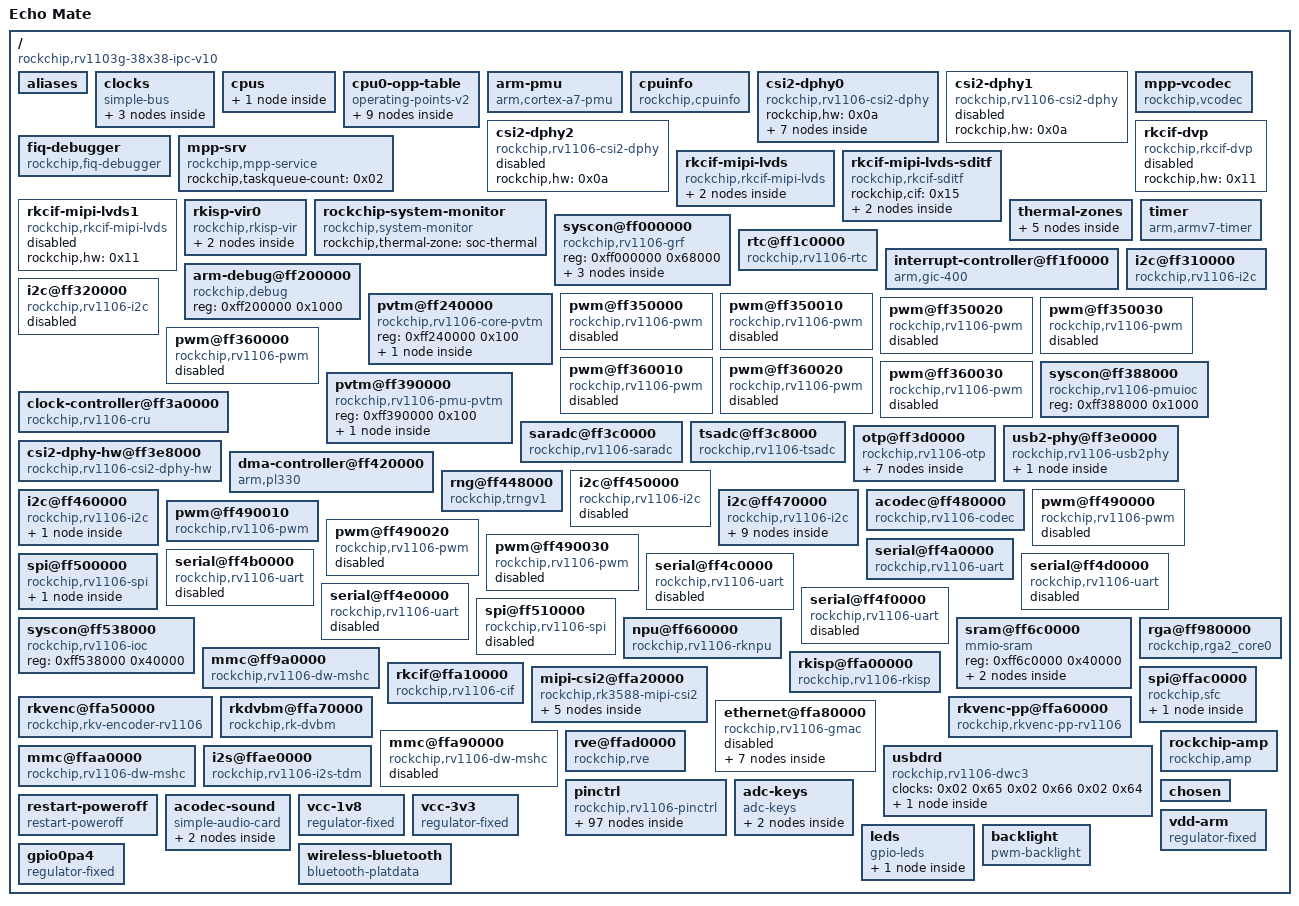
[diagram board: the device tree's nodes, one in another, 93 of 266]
/dts-v1/;

/ {
	#address-cells = <0x01>;
	#size-cells = <0x01>;
	compatible = "rockchip,rv1103g-38x38-ipc-v10\0rockchip,rv1106";
	interrupt-parent = <0x01>;
	model = "Echo Mate";

	aliases {
		csi2dphy0 = "/csi2-dphy0";
		csi2dphy1 = "/csi2-dphy1";
		csi2dphy2 = "/csi2-dphy2";
		ethernet0 = "/ethernet@ffa80000";
		gpio0 = "/pinctrl/gpio@ff380000";
		gpio1 = "/pinctrl/gpio@ff530000";
		gpio2 = "/pinctrl/gpio@ff540000";
		gpio3 = "/pinctrl/gpio@ff550000";
		gpio4 = "/pinctrl/gpio@ff560000";
		i2c0 = "/i2c@ff310000";
		i2c1 = "/i2c@ff320000";
		i2c2 = "/i2c@ff450000";
		i2c3 = "/i2c@ff460000";
		i2c4 = "/i2c@ff470000";
		mmc0 = "/mmc@ffa90000";
		mmc1 = "/mmc@ffaa0000";
		mmc2 = "/mmc@ff9a0000";
		pwm0 = "/pwm@ff350000";
		pwm1 = "/pwm@ff350010";
		pwm2 = "/pwm@ff350020";
		pwm3 = "/pwm@ff350030";
		pwm4 = "/pwm@ff360000";
		pwm5 = "/pwm@ff360010";
		pwm6 = "/pwm@ff360020";
		pwm7 = "/pwm@ff360030";
		pwm8 = "/pwm@ff490000";
		pwm9 = "/pwm@ff490010";
		pwm10 = "/pwm@ff490020";
		pwm11 = "/pwm@ff490030";
		rkcif_mipi_lvds0 = "/rkcif-mipi-lvds";
		rkcif_mipi_lvds1 = "/rkcif-mipi-lvds1";
		serial0 = "/serial@ff4a0000";
		serial1 = "/serial@ff4b0000";
		serial2 = "/serial@ff4c0000";
		serial3 = "/serial@ff4d0000";
		serial4 = "/serial@ff4e0000";
		serial5 = "/serial@ff4f0000";
		spi0 = "/spi@ff500000";
		spi1 = "/spi@ff510000";
		spi2 = "/spi@ffac0000";
	};

	clocks {
		compatible = "simple-bus";

		pvtpll-0 {
			compatible = "fixed-clock";
			clock-frequency = <0x18701a80>;
			clock-output-names = "clk_pvtpll_0";
			#clock-cells = <0x00>;
		};

		pvtpll-1 {
			compatible = "fixed-clock";
			clock-frequency = <0x1908b100>;
			clock-output-names = "clk_pvtpll_1";
			#clock-cells = <0x00>;
		};

		oscillator {
			compatible = "fixed-clock";
			clock-frequency = <0x16e3600>;
			clock-output-names = "xin24m";
			#clock-cells = <0x00>;
		};
	};

	cpus {
		#address-cells = <0x01>;
		#size-cells = <0x00>;

		cpu@0 {
			device_type = "cpu";
			compatible = "arm,cortex-a7";
			reg = <0x00>;
			clocks = <0x02 0x05>;
			operating-points-v2 = <0x03>;
			cpu-supply = <0x04>;
			phandle = <0x06>;
		};
	};

	cpu0-opp-table {
		compatible = "operating-points-v2";
		opp-shared;
		rockchip,pvtpll-avg-offset = <0x4001c>;
		rockchip,pvtpll-min-rate = <0x10d880>;
		rockchip,pvtpll-volt-step = <0x30d4>;
		rockchip,grf = <0x05>;
		phandle = <0x03>;

		opp-408000000 {
			opp-hz = <0x00 0x18519600>;
			opp-microvolt = <0xcf850 0xcf850 0x100590>;
			clock-latency-ns = <0x9c40>;
		};

		opp-600000000 {
			opp-hz = <0x00 0x23c34600>;
			opp-microvolt = <0xcf850 0xcf850 0x100590>;
			clock-latency-ns = <0x9c40>;
		};

		opp-816000000 {
			opp-hz = <0x00 0x30a32c00>;
			opp-microvolt = <0xcf850 0xcf850 0x100590>;
			clock-latency-ns = <0x9c40>;
			opp-suspend;
		};

		opp-1104000000 {
			opp-hz = <0x00 0x41cdb400>;
			opp-microvolt = <0xcf850 0xcf850 0x100590>;
			clock-latency-ns = <0x9c40>;
		};

		opp-1200000000 {
			opp-hz = <0x00 0x47868c00>;
			opp-microvolt = <0xcf850 0xcf850 0x100590>;
			clock-latency-ns = <0x9c40>;
		};

		opp-1296000000 {
			opp-hz = <0x00 0x4d3f6400>;
			opp-microvolt = <0xd59f8 0xcf850 0x100590>;
			clock-latency-ns = <0x9c40>;
		};

		opp-1416000000 {
			opp-hz = <0x00 0x54667200>;
			opp-microvolt = <0xe1d48 0xcf850 0x100590>;
			clock-latency-ns = <0x9c40>;
		};

		opp-1512000000 {
			opp-hz = <0x00 0x5a1f4a00>;
			opp-microvolt = <0xee098 0xcf850 0x100590>;
			clock-latency-ns = <0x9c40>;
		};

		opp-1608000000 {
			opp-hz = <0x00 0x5fd82200>;
			opp-microvolt = <0xf7314 0xcf850 0x100590>;
			clock-latency-ns = <0x9c40>;
		};
	};

	arm-pmu {
		compatible = "arm,cortex-a7-pmu";
		interrupts = <0x00 0x7e 0x04>;
		interrupt-affinity = <0x06>;
	};

	cpuinfo {
		compatible = "rockchip,cpuinfo";
		nvmem-cells = <0x07 0x08 0x09>;
		nvmem-cell-names = "id\0cpu-version\0cpu-code";
	};

	csi2-dphy0 {
		compatible = "rockchip,rv1106-csi2-dphy";
		rockchip,hw = <0x0a>;
		status = "okay";

		ports {
			#address-cells = <0x01>;
			#size-cells = <0x00>;

			port@0 {
				reg = <0x00>;
				#address-cells = <0x01>;
				#size-cells = <0x00>;

				endpoint@0 {
					reg = <0x00>;
					remote-endpoint = <0x0b>;
					data-lanes = <0x01 0x02>;
					phandle = <0x2f>;
				};

				endpoint@1 {
					reg = <0x01>;
					remote-endpoint = <0x0c>;
					data-lanes = <0x01 0x02>;
					phandle = <0x30>;
				};

				endpoint@2 {
					reg = <0x02>;
					remote-endpoint = <0x0d>;
					data-lanes = <0x01 0x02>;
					phandle = <0x31>;
				};
			};

			port@1 {
				reg = <0x01>;
				#address-cells = <0x01>;
				#size-cells = <0x00>;

				endpoint@0 {
					reg = <0x00>;
					remote-endpoint = <0x0e>;
					phandle = <0x4d>;
				};
			};
		};
	};

	csi2-dphy1 {
		compatible = "rockchip,rv1106-csi2-dphy";
		rockchip,hw = <0x0a>;
		status = "disabled";
	};

	csi2-dphy2 {
		compatible = "rockchip,rv1106-csi2-dphy";
		rockchip,hw = <0x0a>;
		status = "disabled";
	};

	fiq-debugger {
		compatible = "rockchip,fiq-debugger";
		rockchip,serial-id = <0x02>;
		rockchip,wake-irq = <0x00>;
		rockchip,irq-mode-enable = <0x01>;
		rockchip,baudrate = <0x1c200>;
		interrupts = <0x00 0x7d 0x04>;
		status = "okay";
	};

	mpp-srv {
		compatible = "rockchip,mpp-service";
		rockchip,taskqueue-count = <0x02>;
		status = "okay";
		phandle = <0x4f>;
	};

	mpp-vcodec {
		compatible = "rockchip,vcodec";
		status = "okay";
	};

	rkcif-dvp {
		compatible = "rockchip,rkcif-dvp";
		rockchip,hw = <0x11>;
		status = "disabled";
		phandle = <0x12>;
	};

	rkcif-mipi-lvds {
		compatible = "rockchip,rkcif-mipi-lvds";
		rockchip,hw = <0x11>;
		status = "okay";
		pinctrl-names = "default";
		pinctrl-0 = <0x13>;
		phandle = <0x15>;

		port {

			endpoint {
				remote-endpoint = <0x14>;
				phandle = <0x4e>;
			};
		};
	};

	rkcif-mipi-lvds-sditf {
		compatible = "rockchip,rkcif-sditf";
		rockchip,cif = <0x15>;
		status = "okay";

		port {

			endpoint {
				remote-endpoint = <0x16>;
				phandle = <0x1a>;
			};
		};
	};

	rkcif-mipi-lvds1 {
		compatible = "rockchip,rkcif-mipi-lvds";
		rockchip,hw = <0x11>;
		status = "disabled";
		phandle = <0x17>;
	};

	rkisp-vir0 {
		compatible = "rockchip,rkisp-vir";
		rockchip,hw = <0x18>;
		dvbm = <0x19>;
		status = "okay";

		port@0 {

			endpoint {
				remote-endpoint = <0x1a>;
				phandle = <0x16>;
			};
		};
	};

	rockchip-system-monitor {
		compatible = "rockchip,system-monitor";
		rockchip,thermal-zone = "soc-thermal";
	};

	thermal-zones {

		soc-thermal {
			polling-delay-passive = <0x14>;
			polling-delay = <0x3e8>;
			sustainable-power = <0x834>;
			thermal-sensors = <0x1b 0x00>;

			trips {

				trip-point-0 {
					temperature = <0x124f8>;
					hysteresis = <0x7d0>;
					type = "passive";
				};

				trip-point-1 {
					temperature = <0x14c08>;
					hysteresis = <0x7d0>;
					type = "passive";
				};

				soc-crit {
					temperature = <0x1c138>;
					hysteresis = <0x7d0>;
					type = "critical";
				};
			};
		};
	};

	timer {
		compatible = "arm,armv7-timer";
		interrupts = <0x01 0x0d 0x104>;
		clock-frequency = <0x16e3600>;
	};

	syscon@ff000000 {
		compatible = "rockchip,rv1106-grf\0syscon\0simple-mfd";
		reg = <0xff000000 0x68000>;
		phandle = <0x05>;

		grf-clock-controller {
			compatible = "rockchip,rv1106-grf-cru";
			#clock-cells = <0x01>;
			phandle = <0x48>;
		};

		reboot-mode {
			compatible = "syscon-reboot-mode";
			offset = <0x20200>;
			mode-bootloader = <0x5242c301>;
			mode-charge = <0x5242c30b>;
			mode-fastboot = <0x5242c309>;
			mode-loader = <0x5242c301>;
			mode-normal = <0x5242c300>;
			mode-recovery = <0x5242c303>;
			mode-ums = <0x5242c30c>;
			mode-panic = <0x5242c307>;
			mode-watchdog = <0x5242c308>;
			mode-uboot = <0x5242c30e>;
		};

		rknpor-powergood {
			compatible = "rockchip,rv1106-npor-powergood";
			interrupts = <0x00 0x56 0x04>;
			status = "okay";
		};
	};

	rtc@ff1c0000 {
		compatible = "rockchip,rv1106-rtc";
		reg = <0xff1c0000 0x1000>;
		rockchip,grf = <0x05>;
		interrupts = <0x00 0x62 0x04>;
		clocks = <0x02 0xef 0x02 0xee>;
		clock-names = "pclk_phy\0pclk_test";
		assigned-clocks = <0x02 0xef>;
		assigned-clock-rates = <0x16e3600>;
		status = "okay";
	};

	interrupt-controller@ff1f0000 {
		compatible = "arm,gic-400";
		interrupt-controller;
		#interrupt-cells = <0x03>;
		#address-cells = <0x00>;
		reg = <0xff1f1000 0x1000 0xff1f2000 0x2000 0xff1f4000 0x2000 0xff1f6000 0x2000>;
		interrupts = <0x01 0x09 0x104>;
		phandle = <0x01>;
	};

	arm-debug@ff200000 {
		compatible = "rockchip,debug";
		reg = <0xff200000 0x1000>;
	};

	pvtm@ff240000 {
		compatible = "rockchip,rv1106-core-pvtm";
		reg = <0xff240000 0x100>;
		#address-cells = <0x01>;
		#size-cells = <0x00>;

		pvtm@0 {
			reg = <0x00>;
			clocks = <0x02 0x40>;
			clock-names = "clk";
			resets = <0x02 0x6000e 0x02 0x6000f>;
			reset-names = "rst\0rst-p";
		};
	};

	i2c@ff310000 {
		compatible = "rockchip,rv1106-i2c\0rockchip,rk3399-i2c";
		reg = <0xff310000 0x1000>;
		interrupts = <0x00 0x12 0x04>;
		#address-cells = <0x01>;
		#size-cells = <0x00>;
		clocks = <0x02 0x2a 0x02 0x29>;
		clock-names = "i2c\0pclk";
		pinctrl-names = "default";
		pinctrl-0 = <0x1c>;
		status = "okay";
		clock-frequency = <0x186a0>;
	};

	i2c@ff320000 {
		compatible = "rockchip,rv1106-i2c\0rockchip,rk3399-i2c";
		reg = <0xff320000 0x1000>;
		interrupts = <0x00 0x13 0x04>;
		#address-cells = <0x01>;
		#size-cells = <0x00>;
		clocks = <0x02 0x78 0x02 0x77>;
		clock-names = "i2c\0pclk";
		pinctrl-names = "default";
		pinctrl-0 = <0x1d>;
		status = "disabled";
		clock-frequency = <0x186a0>;
	};

	pwm@ff350000 {
		compatible = "rockchip,rv1106-pwm\0rockchip,rk3328-pwm";
		reg = <0xff350000 0x10>;
		#pwm-cells = <0x03>;
		pinctrl-names = "active";
		pinctrl-0 = <0x1f>;
		clocks = <0x02 0x36 0x02 0x35>;
		clock-names = "pwm\0pclk";
		status = "disabled";
	};

	pwm@ff350010 {
		compatible = "rockchip,rv1106-pwm\0rockchip,rk3328-pwm";
		reg = <0xff350010 0x10>;
		#pwm-cells = <0x03>;
		pinctrl-names = "active";
		pinctrl-0 = <0x20>;
		clocks = <0x02 0x36 0x02 0x35>;
		clock-names = "pwm\0pclk";
		status = "disabled";
	};

	pwm@ff350020 {
		compatible = "rockchip,rv1106-pwm\0rockchip,rk3328-pwm";
		reg = <0xff350020 0x10>;
		#pwm-cells = <0x03>;
		pinctrl-names = "active";
		pinctrl-0 = <0x21>;
		clocks = <0x02 0x36 0x02 0x35>;
		clock-names = "pwm\0pclk";
		status = "disabled";
	};

	pwm@ff350030 {
		compatible = "rockchip,rv1106-pwm\0rockchip,rk3328-pwm";
		reg = <0xff350030 0x10>;
		interrupts = <0x00 0x1f 0x04 0x00 0x20 0x04>;
		#pwm-cells = <0x03>;
		pinctrl-names = "active";
		pinctrl-0 = <0x22>;
		clocks = <0x02 0x36 0x02 0x35>;
		clock-names = "pwm\0pclk";
		status = "disabled";
	};

	pwm@ff360000 {
		compatible = "rockchip,rv1106-pwm\0rockchip,rk3328-pwm";
		reg = <0xff360000 0x10>;
		#pwm-cells = <0x03>;
		pinctrl-names = "active";
		pinctrl-0 = <0x23>;
		clocks = <0x02 0x44 0x02 0x43>;
		clock-names = "pwm\0pclk";
		status = "disabled";
	};

	pwm@ff360010 {
		compatible = "rockchip,rv1106-pwm\0rockchip,rk3328-pwm";
		reg = <0xff360010 0x10>;
		#pwm-cells = <0x03>;
		pinctrl-names = "active";
		pinctrl-0 = <0x24>;
		clocks = <0x02 0x44 0x02 0x43>;
		clock-names = "pwm\0pclk";
		status = "disabled";
	};

	pwm@ff360020 {
		compatible = "rockchip,rv1106-pwm\0rockchip,rk3328-pwm";
		reg = <0xff360020 0x10>;
		#pwm-cells = <0x03>;
		pinctrl-names = "active";
		pinctrl-0 = <0x25 0x26>;
		clocks = <0x02 0x44 0x02 0x43>;
		clock-names = "pwm\0pclk";
		status = "disabled";
	};

	pwm@ff360030 {
		compatible = "rockchip,rv1106-pwm\0rockchip,rk3328-pwm";
		reg = <0xff360030 0x10>;
		interrupts = <0x00 0x21 0x04 0x00 0x22 0x04>;
		#pwm-cells = <0x03>;
		pinctrl-names = "active";
		pinctrl-0 = <0x27>;
		clocks = <0x02 0x44 0x02 0x43>;
		clock-names = "pwm\0pclk";
		status = "disabled";
	};

	syscon@ff388000 {
		compatible = "rockchip,rv1106-pmuioc\0syscon";
		reg = <0xff388000 0x1000>;
		phandle = <0x5d>;
	};

	pvtm@ff390000 {
		compatible = "rockchip,rv1106-pmu-pvtm";
		reg = <0xff390000 0x100>;
		#address-cells = <0x01>;
		#size-cells = <0x00>;

		pvtm@0 {
			reg = <0x01>;
			clocks = <0x02 0x7e 0x02 0x7f>;
			clock-names = "clk\0pclk";
			resets = <0x02 0x14 0x02 0x15>;
			reset-names = "rst\0rst-p";
		};
	};

	clock-controller@ff3a0000 {
		compatible = "rockchip,rv1106-cru";
		reg = <0xff3a0000 0x20000>;
		rockchip,grf = <0x05>;
		#clock-cells = <0x01>;
		#reset-cells = <0x01>;
		assigned-clocks = <0x02 0x04 0x02 0x03 0x02 0x05 0x02 0x39 0x02 0x3a 0x02 0x38 0x02 0x3c 0x02 0xcb 0x02 0x82 0x02 0x83>;
		assigned-clock-rates = <0x46cf7100 0x3b9aca00 0x41cdb400 0x17d78400 0xbebc200 0x5f5e100 0x11e1a300 0x5f5e100 0x5f5e100 0xbebc200>;
		phandle = <0x02>;
	};

	saradc@ff3c0000 {
		compatible = "rockchip,rv1106-saradc";
		reg = <0xff3c0000 0x200>;
		interrupts = <0x00 0x3e 0x04>;
		#io-channel-cells = <0x01>;
		clocks = <0x02 0x4d 0x02 0x4c>;
		clock-names = "saradc\0apb_pclk";
		resets = <0x02 0x48033>;
		reset-names = "saradc-apb";
		status = "okay";
		vref-supply = <0x28>;
		phandle = <0x68>;
	};

	tsadc@ff3c8000 {
		compatible = "rockchip,rv1106-tsadc";
		reg = <0xff3c8000 0x1000>;
		rockchip,grf = <0x05>;
		interrupts = <0x00 0x61 0x04>;
		clocks = <0x02 0x113 0x02 0x112 0x02 0x114>;
		clock-names = "tsadc\0apb_pclk\0tsen";
		assigned-clocks = <0x02 0x113 0x02 0x114>;
		assigned-clock-rates = <0xf4240 0xb71b00>;
		resets = <0x02 0x70021 0x02 0x70020>;
		reset-names = "tsadc\0tsadc-apb";
		#thermal-sensor-cells = <0x01>;
		rockchip,hw-tshut-temp = <0x1d4c0>;
		rockchip,hw-tshut-mode = <0x00>;
		rockchip,hw-tshut-polarity = <0x00>;
		status = "okay";
		phandle = <0x1b>;
	};

	otp@ff3d0000 {
		compatible = "rockchip,rv1106-otp";
		reg = <0xff3d0000 0x4000>;
		#address-cells = <0x01>;
		#size-cells = <0x01>;
		clocks = <0x02 0x107 0x02 0x106 0x02 0x105 0x02 0x10b 0x02 0x104 0x02 0x10c>;
		clock-names = "usr\0sbpi\0apb\0phy\0arb\0pmc";
		resets = <0x02 0x70026 0x02 0x70025 0x02 0x70023 0x02 0x7002e 0x02 0x7002b 0x02 0x7002f>;
		reset-names = "usr\0sbpi\0apb\0phy\0arb\0pmc";

		cpu-code@2 {
			reg = <0x02 0x02>;
			phandle = <0x09>;
		};

		cpu-version@8 {
			reg = <0x08 0x01>;
			bits = <0x03 0x03>;
			phandle = <0x08>;
		};

		id@a {
			reg = <0x0a 0x10>;
			phandle = <0x07>;
		};

		cpu-leakage@1a {
			reg = <0x1a 0x01>;
		};

		log-leakage@1b {
			reg = <0x1b 0x01>;
		};

		macphy-bgs@2d {
			reg = <0x2d 0x01>;
			phandle = <0x54>;
		};

		macphy-txlevel@2e {
			reg = <0x2e 0x02>;
			phandle = <0x55>;
		};
	};

	usb2-phy@ff3e0000 {
		compatible = "rockchip,rv1106-usb2phy";
		reg = <0xff3e0000 0x8000>;
		rockchip,usbgrf = <0x05>;
		clocks = <0x02 0x68 0x02 0x67>;
		clock-names = "phyclk\0pclk";
		resets = <0x02 0x48052 0x02 0x48051>;
		reset-names = "u2phy\0u2phy-apb";
		#clock-cells = <0x00>;
		status = "okay";
		phandle = <0x5b>;

		otg-port {
			#phy-cells = <0x00>;
			interrupts = <0x00 0x3a 0x04 0x00 0x3b 0x04 0x00 0x3c 0x04 0x00 0x3d 0x04>;
			interrupt-names = "otg-bvalid\0otg-id\0linestate\0disconnect";
			status = "okay";
			phandle = <0x5a>;
		};
	};

	csi2-dphy-hw@ff3e8000 {
		compatible = "rockchip,rv1106-csi2-dphy-hw";
		reg = <0xff3e8000 0x8000>;
		clocks = <0x02 0xe6>;
		clock-names = "pclk";
		resets = <0x02 0x5001e>;
		reset-names = "srst_p_csiphy";
		rockchip,grf = <0x05>;
		status = "okay";
		phandle = <0x0a>;
	};

	dma-controller@ff420000 {
		compatible = "arm,pl330\0arm,primecell";
		reg = <0xff420000 0x4000>;
		interrupts = <0x00 0x3f 0x04 0x00 0x40 0x04 0x00 0x41 0x04 0x00 0x42 0x04 0x00 0x43 0x04 0x00 0x44 0x04 0x00 0x45 0x04 0x00 0x46 0x04 0x00 0x4f 0x04>;
		#dma-cells = <0x01>;
		clocks = <0x02 0x22>;
		clock-names = "apb_pclk";
		arm,pl330-periph-burst;
		phandle = <0x37>;
	};

	rng@ff448000 {
		compatible = "rockchip,trngv1";
		reg = <0xff448000 0x200>;
		interrupts = <0x00 0x11 0x04>;
		clocks = <0x02 0x5a>;
		clock-names = "hclk_trng";
		resets = <0x02 0x48039>;
		reset-names = "reset";
		status = "okay";
	};

	i2c@ff450000 {
		compatible = "rockchip,rv1106-i2c\0rockchip,rk3399-i2c";
		reg = <0xff450000 0x1000>;
		interrupts = <0x00 0x14 0x04>;
		#address-cells = <0x01>;
		#size-cells = <0x00>;
		clocks = <0x02 0x2c 0x02 0x2b>;
		clock-names = "i2c\0pclk";
		pinctrl-names = "default";
		pinctrl-0 = <0x29>;
		status = "disabled";
	};

	i2c@ff460000 {
		compatible = "rockchip,rv1106-i2c\0rockchip,rk3399-i2c";
		reg = <0xff460000 0x1000>;
		interrupts = <0x00 0x15 0x04>;
		#address-cells = <0x01>;
		#size-cells = <0x00>;
		clocks = <0x02 0x2e 0x02 0x2d>;
		clock-names = "i2c\0pclk";
		pinctrl-names = "default";
		pinctrl-0 = <0x2a>;
		status = "okay";
		clock-frequency = <0x186a0>;

		focaltech@38 {
			compatible = "focaltech,fts";
			reg = <0x38>;
			interrupt-parent = <0x2b>;
			interrupts = <0x17 0x02>;
			focaltech,reset-gpio = <0x2b 0x16 0x01>;
			focaltech,irq-gpio = <0x2b 0x17 0x08>;
			focaltech,max-touch-number = <0x05>;
			focaltech,display-coords = <0x00 0x00 0xf0 0x140>;
			focaltech,rotate = <0x10e>;
		};
	};

	i2c@ff470000 {
		compatible = "rockchip,rv1106-i2c\0rockchip,rk3399-i2c";
		reg = <0xff470000 0x1000>;
		interrupts = <0x00 0x16 0x04>;
		#address-cells = <0x01>;
		#size-cells = <0x00>;
		clocks = <0x02 0x30 0x02 0x2f>;
		clock-names = "i2c\0pclk";
		pinctrl-names = "default";
		pinctrl-0 = <0x2c>;
		status = "okay";
		clock-frequency = <0x61a80>;

		sc3336@30 {
			compatible = "smartsens,sc3336";
			status = "okay";
			reg = <0x30>;
			clocks = <0x02 0xa5>;
			clock-names = "xvclk";
			pwdn-gpios = <0x2d 0x15 0x00>;
			pinctrl-names = "default";
			pinctrl-0 = <0x2e>;
			rockchip,camera-module-index = <0x00>;
			rockchip,camera-module-facing = "back";
			rockchip,camera-module-name = "CMK-OT2119-PC1";
			rockchip,camera-module-lens-name = "30IRC-F16";

			port {

				endpoint {
					remote-endpoint = <0x2f>;
					data-lanes = <0x01 0x02>;
					phandle = <0x0b>;
				};
			};
		};

		sc4336@30 {
			compatible = "smartsens,sc4336";
			status = "okay";
			reg = <0x30>;
			clocks = <0x02 0xa5>;
			clock-names = "xvclk";
			pwdn-gpios = <0x2d 0x15 0x00>;
			pinctrl-names = "default";
			pinctrl-0 = <0x2e>;
			rockchip,camera-module-index = <0x00>;
			rockchip,camera-module-facing = "back";
			rockchip,camera-module-name = "OT01";
			rockchip,camera-module-lens-name = "40IRC_F16";

			port {

				endpoint {
					remote-endpoint = <0x30>;
					data-lanes = <0x01 0x02>;
					phandle = <0x0c>;
				};
			};
		};

		sc530ai@30 {
			compatible = "smartsens,sc530ai";
			status = "okay";
			reg = <0x30>;
			clocks = <0x02 0xa5>;
			clock-names = "xvclk";
			pwdn-gpios = <0x2d 0x15 0x00>;
			pinctrl-names = "default";
			pinctrl-0 = <0x2e>;
			rockchip,camera-module-index = <0x00>;
			rockchip,camera-module-facing = "back";
			rockchip,camera-module-name = "CMK-OT2115-PC1";
			rockchip,camera-module-lens-name = "30IRC-F16";

			port {

				endpoint {
					remote-endpoint = <0x31>;
					data-lanes = <0x01 0x02>;
					phandle = <0x0d>;
				};
			};
		};
	};

	acodec@ff480000 {
		compatible = "rockchip,rv1106-codec";
		reg = <0xff480000 0x1000>;
		rockchip,grf = <0x05>;
		clocks = <0x02 0x18 0x02 0x19 0x02 0x9f>;
		clock-names = "pclk_acodec\0mclk_acodec\0mclk_cpu";
		resets = <0x02 0x48063>;
		reset-names = "acodec-reset";
		acodec,micbias;
		init-mic-gain = <0x22>;
		status = "okay";
		#sound-dai-cells = <0x00>;
		pa-ctl-gpios = <0x32 0x02 0x01>;
		phandle = <0x6a>;
	};

	pwm@ff490000 {
		compatible = "rockchip,rv1106-pwm\0rockchip,rk3328-pwm";
		reg = <0xff490000 0x10>;
		#pwm-cells = <0x03>;
		pinctrl-names = "active";
		pinctrl-0 = <0x33>;
		clocks = <0x02 0x47 0x02 0x46>;
		clock-names = "pwm\0pclk";
		status = "disabled";
	};

	pwm@ff490010 {
		compatible = "rockchip,rv1106-pwm\0rockchip,rk3328-pwm";
		reg = <0xff490010 0x10>;
		#pwm-cells = <0x03>;
		pinctrl-names = "active";
		pinctrl-0 = <0x34>;
		clocks = <0x02 0x47 0x02 0x46>;
		clock-names = "pwm\0pclk";
		status = "okay";
		phandle = <0x6b>;
	};

	pwm@ff490020 {
		compatible = "rockchip,rv1106-pwm\0rockchip,rk3328-pwm";
		reg = <0xff490020 0x10>;
		#pwm-cells = <0x03>;
		pinctrl-names = "active";
		pinctrl-0 = <0x35>;
		clocks = <0x02 0x47 0x02 0x46>;
		clock-names = "pwm\0pclk";
		status = "disabled";
	};

	pwm@ff490030 {
		compatible = "rockchip,rv1106-pwm\0rockchip,rk3328-pwm";
		reg = <0xff490030 0x10>;
		interrupts = <0x00 0x23 0x04 0x00 0x24 0x04>;
		#pwm-cells = <0x03>;
		pinctrl-names = "active";
		pinctrl-0 = <0x36>;
		clocks = <0x02 0x47 0x02 0x46>;
		clock-names = "pwm\0pclk";
		status = "disabled";
	};

	serial@ff4a0000 {
		compatible = "rockchip,rv1106-uart\0snps,dw-apb-uart";
		reg = <0xff4a0000 0x100>;
		interrupts = <0x00 0x19 0x04>;
		reg-shift = <0x02>;
		reg-io-width = <0x04>;
		dmas = <0x37 0x07 0x37 0x06>;
		clock-frequency = <0x16e3600>;
		clocks = <0x02 0xac 0x02 0x3f>;
		clock-names = "baudclk\0apb_pclk";
		pinctrl-names = "default";
		pinctrl-0 = <0x38 0x39 0x3a>;
		status = "okay";
	};

	serial@ff4b0000 {
		compatible = "rockchip,rv1106-uart\0snps,dw-apb-uart";
		reg = <0xff4b0000 0x100>;
		interrupts = <0x00 0x1a 0x04>;
		reg-shift = <0x02>;
		reg-io-width = <0x04>;
		dmas = <0x37 0x09 0x37 0x08>;
		clock-frequency = <0x16e3600>;
		clocks = <0x02 0xb0 0x02 0x41>;
		clock-names = "baudclk\0apb_pclk";
		pinctrl-names = "default";
		pinctrl-0 = <0x3b>;
		status = "disabled";
	};

	serial@ff4c0000 {
		compatible = "rockchip,rv1106-uart\0snps,dw-apb-uart";
		reg = <0xff4c0000 0x100>;
		interrupts = <0x00 0x1b 0x04>;
		reg-shift = <0x02>;
		reg-io-width = <0x04>;
		dmas = <0x37 0x0b 0x37 0x0a>;
		clock-frequency = <0x16e3600>;
		clocks = <0x02 0xb4 0x02 0x5c>;
		clock-names = "baudclk\0apb_pclk";
		pinctrl-names = "default";
		pinctrl-0 = <0x3c>;
		status = "disabled";
	};

	serial@ff4d0000 {
		compatible = "rockchip,rv1106-uart\0snps,dw-apb-uart";
		reg = <0xff4d0000 0x100>;
		interrupts = <0x00 0x1c 0x04>;
		reg-shift = <0x02>;
		reg-io-width = <0x04>;
		dmas = <0x37 0x0d 0x37 0x0c>;
		clock-frequency = <0x16e3600>;
		clocks = <0x02 0xb8 0x02 0x5e>;
		clock-names = "baudclk\0apb_pclk";
		pinctrl-names = "default";
		pinctrl-0 = <0x3d>;
		status = "disabled";
	};

	serial@ff4e0000 {
		compatible = "rockchip,rv1106-uart\0snps,dw-apb-uart";
		reg = <0xff4e0000 0x100>;
		interrupts = <0x00 0x1d 0x04>;
		reg-shift = <0x02>;
		reg-io-width = <0x04>;
		dmas = <0x37 0x0f 0x37 0x0e>;
		clock-frequency = <0x16e3600>;
		clocks = <0x02 0xbc 0x02 0x60>;
		clock-names = "baudclk\0apb_pclk";
		pinctrl-names = "default";
		pinctrl-0 = <0x3e>;
		status = "disabled";
	};

	serial@ff4f0000 {
		compatible = "rockchip,rv1106-uart\0snps,dw-apb-uart";
		reg = <0xff4f0000 0x100>;
		interrupts = <0x00 0x1e 0x04>;
		reg-shift = <0x02>;
		reg-io-width = <0x04>;
		dmas = <0x37 0x11 0x37 0x10>;
		clock-frequency = <0x16e3600>;
		clocks = <0x02 0xc0 0x02 0x62>;
		clock-names = "baudclk\0apb_pclk";
		pinctrl-names = "default";
		pinctrl-0 = <0x3f>;
		status = "disabled";
	};

	spi@ff500000 {
		compatible = "rockchip,rv1106-spi\0rockchip,rk3066-spi";
		reg = <0xff500000 0x1000>;
		interrupts = <0x00 0x17 0x04>;
		#address-cells = <0x01>;
		#size-cells = <0x00>;
		clocks = <0x02 0xcd 0x02 0xcc 0x02 0xce>;
		clock-names = "spiclk\0apb_pclk\0sclk_in";
		dmas = <0x37 0x01 0x37 0x00>;
		dma-names = "tx\0rx";
		pinctrl-names = "default";
		pinctrl-0 = <0x40 0x41 0x42 0x43>;
		status = "okay";

		fbtft@0 {
			compatible = "sitronix,st7789v";
			reg = <0x00>;
			spi-max-frequency = <0x3938700>;
			fps = <0x3c>;
			buswidth = <0x08>;
			debug = <0x07>;
			rotate = <0x10e>;
			dc-gpios = <0x2b 0x18 0x00>;
			reset-gpios = <0x2b 0x14 0x01>;
		};
	};

	spi@ff510000 {
		compatible = "rockchip,rv1106-spi\0rockchip,rk3066-spi";
		reg = <0xff510000 0x1000>;
		interrupts = <0x00 0x18 0x04>;
		#address-cells = <0x01>;
		#size-cells = <0x00>;
		clocks = <0x02 0x4f 0x02 0x4e>;
		clock-names = "spiclk\0apb_pclk";
		dmas = <0x37 0x03 0x37 0x02>;
		dma-names = "tx\0rx";
		pinctrl-names = "default";
		pinctrl-0 = <0x44 0x45 0x46>;
		status = "disabled";
	};

	syscon@ff538000 {
		compatible = "rockchip,rv1106-ioc\0syscon";
		reg = <0xff538000 0x40000>;
		phandle = <0x5c>;
	};

	npu@ff660000 {
		compatible = "rockchip,rv1106-rknpu";
		reg = <0xff660000 0x10000>;
		interrupts = <0x00 0x6d 0x04>;
		clocks = <0x02 0x17 0x02 0x16>;
		clock-names = "aclk\0hclk";
		assigned-clocks = <0x02 0x17>;
		assigned-clock-rates = <0x1908b100>;
		resets = <0x02 0x5800a 0x02 0x58009>;
		reset-names = "srst_a\0srst_h";
		status = "okay";
	};

	sram@ff6c0000 {
		compatible = "mmio-sram";
		reg = <0xff6c0000 0x40000>;
		#address-cells = <0x01>;
		#size-cells = <0x01>;
		ranges = <0x00 0xff6c0000 0x40000>;

		rkisp-sram@0 {
			reg = <0x00 0x3f000>;
			phandle = <0x4c>;
		};

		hpmcu-sram@3f000 {
			reg = <0x3f000 0x1000>;
		};
	};

	rga@ff980000 {
		compatible = "rockchip,rga2_core0";
		reg = <0xff980000 0x1000>;
		interrupts = <0x00 0x57 0x04>;
		clocks = <0x02 0x10e 0x02 0x10d 0x02 0x10f>;
		clock-names = "aclk_rga2\0hclk_rga2\0clk_rga2";
		status = "okay";
	};

	mmc@ff9a0000 {
		compatible = "rockchip,rv1106-dw-mshc\0rockchip,rk3288-dw-mshc";
		reg = <0xff9a0000 0x4000>;
		interrupts = <0x00 0x31 0x04>;
		clocks = <0x02 0x111 0x02 0x110 0x48 0x05 0x48 0x06>;
		clock-names = "biu\0ciu\0ciu-drive\0ciu-sample";
		fifo-depth = <0x100>;
		max-frequency = <0x2faf080>;
		status = "okay";
		bus-width = <0x04>;
		cap-sd-highspeed;
		cap-sdio-irq;
		keep-power-in-suspend;
		non-removable;
		sd-uhs-sdr50;
		no-1-8-v;
		supports-sdio;
		pinctrl-names = "default";
		pinctrl-0 = <0x49 0x4a 0x4b>;
	};

	rkisp@ffa00000 {
		compatible = "rockchip,rv1106-rkisp";
		reg = <0xffa00000 0x7f00>;
		interrupts = <0x00 0x69 0x04 0x00 0x68 0x04 0x00 0x67 0x04>;
		interrupt-names = "isp_irq\0mi_irq\0mipi_irq";
		clocks = <0x02 0xe4 0x02 0xe3 0x02 0xe5 0x02 0xf8>;
		clock-names = "aclk_isp\0hclk_isp\0clk_isp_core\0clk_isp_core_vicap";
		rockchip,sram = <0x4c>;
		status = "okay";
		phandle = <0x18>;
	};

	rkcif@ffa10000 {
		compatible = "rockchip,rv1106-cif";
		reg = <0xffa10000 0x10000>;
		reg-names = "cif_regs";
		interrupts = <0x00 0x6a 0x04>;
		interrupt-names = "cif-intr";
		clocks = <0x02 0xf2 0x02 0xf3 0x02 0xf0 0x02 0xf1 0x02 0xf4 0x02 0xf5 0x02 0xf6 0x02 0xf7 0x02 0xf8 0x02 0xc4 0x02 0xc8 0x02 0xdc>;
		clock-names = "aclk_cif\0hclk_cif\0dclk_cif\0pclk_cif\0i0clk_cif\0i1clk_cif\0rx0clk_cif\0rx1clk_cif\0isp0clk_cif\0sclk_m0_cif\0sclk_m1_cif\0pclk_vepu_cif";
		resets = <0x02 0x5000c 0x02 0x5000d 0x02 0x5000a 0x02 0x5000b 0x02 0x5000e 0x02 0x5000f 0x02 0x50010 0x02 0x50011 0x02 0x50012 0x02 0x6800e>;
		reset-names = "rst_cif_a\0rst_cif_h\0rst_cif_d\0rst_cif_p\0rst_cif_i0\0rst_cif_i1\0rst_cif_rx0\0rst_cif_rx1\0rst_cif_isp0\0rst_cif_pclk_vepu";
		rockchip,grf = <0x05>;
		status = "okay";
		phandle = <0x11>;
	};

	mipi-csi2@ffa20000 {
		compatible = "rockchip,rk3588-mipi-csi2";
		reg = <0xffa20000 0x10000>;
		reg-names = "csihost_regs";
		interrupts = <0x00 0x63 0x04 0x00 0x64 0x04>;
		interrupt-names = "csi-intr1\0csi-intr2";
		clocks = <0x02 0xdd 0x02 0xde>;
		clock-names = "pclk_csi2host\0clk_rxbyte_hs";
		resets = <0x02 0x50014>;
		reset-names = "srst_csihost_p";
		status = "okay";

		ports {
			#address-cells = <0x01>;
			#size-cells = <0x00>;

			port@0 {
				reg = <0x00>;
				#address-cells = <0x01>;
				#size-cells = <0x00>;

				endpoint@1 {
					reg = <0x01>;
					remote-endpoint = <0x4d>;
					phandle = <0x0e>;
				};
			};

			port@1 {
				reg = <0x01>;
				#address-cells = <0x01>;
				#size-cells = <0x00>;

				endpoint@0 {
					reg = <0x00>;
					remote-endpoint = <0x4e>;
					phandle = <0x14>;
				};
			};
		};
	};

	rkvenc@ffa50000 {
		compatible = "rockchip,rkv-encoder-rv1106";
		reg = <0xffa50000 0x6000>;
		interrupts = <0x00 0x6b 0x04>;
		interrupt-names = "irq_rkvenc";
		clocks = <0x02 0xd1 0x02 0xd0 0x02 0xd2>;
		clock-names = "aclk_vcodec\0hclk_vcodec\0clk_core";
		rockchip,normal-rates = <0x11e1a300 0x00 0x18701a80>;
		assigned-clocks = <0x02 0xd1 0x02 0xd2>;
		assigned-clock-rates = <0x11e1a300 0x17d78400>;
		resets = <0x02 0x68009 0x02 0x68008 0x02 0x6800a>;
		reset-names = "video_a\0video_h\0video_core";
		rockchip,srv = <0x4f>;
		rockchip,taskqueue-node = <0x00>;
		dvbm = <0x19>;
		status = "okay";
	};

	rkvenc-pp@ffa60000 {
		compatible = "rockchip,rkvenc-pp-rv1106";
		reg = <0xffa60000 0x900>;
		interrupts = <0x00 0x6c 0x04>;
		interrupt-names = "irq_rkvenc_pp";
		clocks = <0x02 0xd7 0x02 0xd6>;
		clock-names = "aclk_vepu_pp\0hclk_vepu_pp";
		assigned-clocks = <0x02 0xd7 0x02 0xd6>;
		resets = <0x02 0x6800c 0x02 0x6800b>;
		rockchip,srv = <0x4f>;
		rockchip,taskqueue-node = <0x01>;
		status = "okay";
	};

	rkdvbm@ffa70000 {
		compatible = "rockchip,rk-dvbm";
		reg = <0xffa70000 0x90>;
		interrupts = <0x00 0x74 0x04>;
		interrupt-names = "irq_rkdvbm";
		clocks = <0x02 0xd3>;
		clock-names = "clk_core";
		assigned-clocks = <0x02 0xd3>;
		assigned-clock-rates = <0xbebc200>;
		resets = <0x02 0x6800d>;
		reset-names = "dvbm_rst";
		status = "okay";
		phandle = <0x19>;
	};

	ethernet@ffa80000 {
		compatible = "rockchip,rv1106-gmac\0snps,dwmac-4.20a";
		reg = <0xffa80000 0x10000>;
		interrupts = <0x00 0x5d 0x04 0x00 0x60 0x04>;
		interrupt-names = "macirq\0eth_wake_irq";
		rockchip,grf = <0x05>;
		clocks = <0x02 0xfe 0x02 0xff 0x02 0xfb 0x02 0xfc>;
		clock-names = "stmmaceth\0clk_mac_ref\0aclk_mac\0pclk_mac";
		resets = <0x02 0x70018>;
		reset-names = "stmmaceth";
		snps,mixed-burst;
		snps,tso;
		tx-dma-size = <0x100>;
		rx-dma-size = <0x10>;
		snps,axi-config = <0x50>;
		snps,mtl-rx-config = <0x51>;
		snps,mtl-tx-config = <0x52>;
		phy-mode = "rmii";
		clock_in_out = "input";
		phy-handle = <0x53>;
		nvmem-cells = <0x54>;
		nvmem-cell-names = "bgs";
		status = "disabled";

		mdio {
			compatible = "snps,dwmac-mdio";
			#address-cells = <0x01>;
			#size-cells = <0x00>;

			ethernet-phy@2 {
				compatible = "ethernet-phy-id0044.1400\0ethernet-phy-ieee802.3-c22";
				reg = <0x02>;
				clocks = <0x02 0x103>;
				resets = <0x02 0x7002d>;
				phy-is-integrated;
				nvmem-cells = <0x55>;
				nvmem-cell-names = "txlevel";
				phandle = <0x53>;
			};
		};

		stmmac-axi-config {
			snps,wr_osr_lmt = <0x04>;
			snps,rd_osr_lmt = <0x08>;
			snps,blen = <0x00 0x00 0x00 0x00 0x10 0x08 0x04>;
			phandle = <0x50>;
		};

		rx-queues-config {
			snps,rx-queues-to-use = <0x01>;
			phandle = <0x51>;

			queue0 {
				status = "okay";
			};
		};

		tx-queues-config {
			snps,tx-queues-to-use = <0x01>;
			phandle = <0x52>;

			queue0 {
				status = "okay";
			};
		};
	};

	mmc@ffa90000 {
		compatible = "rockchip,rv1106-dw-mshc\0rockchip,rk3288-dw-mshc";
		reg = <0xffa90000 0x4000>;
		interrupts = <0x00 0x30 0x04>;
		clocks = <0x02 0x26 0x02 0x25 0x48 0x01 0x48 0x02>;
		clock-names = "biu\0ciu\0ciu-drive\0ciu-sample";
		fifo-depth = <0x100>;
		max-frequency = <0xbebc200>;
		rockchip,use-v2-tuning;
		status = "disabled";
	};

	mmc@ffaa0000 {
		compatible = "rockchip,rv1106-dw-mshc\0rockchip,rk3288-dw-mshc";
		reg = <0xffaa0000 0x4000>;
		interrupts = <0x00 0x34 0x04>;
		clocks = <0x02 0xe8 0x02 0xe7 0x48 0x03 0x48 0x04>;
		clock-names = "biu\0ciu\0ciu-drive\0ciu-sample";
		fifo-depth = <0x100>;
		max-frequency = <0x2faf080>;
		status = "okay";
		no-sdio;
		no-mmc;
		bus-width = <0x04>;
		cap-mmc-highspeed;
		cap-sd-highspeed;
		disable-wp;
		pinctrl-names = "default";
		pinctrl-0 = <0x56 0x57 0x58 0x59>;
	};

	spi@ffac0000 {
		compatible = "rockchip,sfc";
		reg = <0xffac0000 0x4000>;
		interrupts = <0x00 0x35 0x04>;
		clocks = <0x02 0x3e 0x02 0x3d>;
		clock-names = "clk_sfc\0hclk_sfc";
		assigned-clocks = <0x02 0x3e>;
		assigned-clock-rates = <0x47868c0>;
		#address-cells = <0x01>;
		#size-cells = <0x00>;
		status = "okay";

		flash@0 {
			compatible = "spi-nand";
			reg = <0x00>;
			spi-max-frequency = <0x47868c0>;
			spi-rx-bus-width = <0x04>;
			spi-tx-bus-width = <0x01>;
		};
	};

	rve@ffad0000 {
		compatible = "rockchip,rve";
		reg = <0xffad0000 0x1000>;
		interrupts = <0x00 0x6f 0x04>;
		clocks = <0x02 0x34 0x02 0x33>;
		clock-names = "aclk_rve\0hclk_rve";
		status = "okay";
	};

	i2s@ffae0000 {
		compatible = "rockchip,rv1106-i2s-tdm";
		reg = <0xffae0000 0x1000>;
		interrupts = <0x00 0x50 0x04>;
		clocks = <0x02 0x9f 0x02 0x9e 0x02 0x31>;
		clock-names = "mclk_tx\0mclk_rx\0hclk";
		dmas = <0x37 0x16 0x37 0x15>;
		dma-names = "tx\0rx";
		resets = <0x02 0x4805f 0x02 0x48066>;
		reset-names = "tx-m\0rx-m";
		rockchip,clk-trcm = <0x01>;
		#sound-dai-cells = <0x00>;
		status = "okay";
		phandle = <0x69>;
	};

	usbdrd {
		compatible = "rockchip,rv1106-dwc3\0rockchip,rk3399-dwc3";
		clocks = <0x02 0x65 0x02 0x66 0x02 0x64>;
		clock-names = "ref\0utmi\0bus";
		#address-cells = <0x01>;
		#size-cells = <0x01>;
		ranges;
		status = "okay";

		usb@ffb00000 {
			compatible = "snps,dwc3";
			reg = <0xffb00000 0x100000>;
			interrupts = <0x00 0x36 0x04>;
			resets = <0x02 0x48047>;
			reset-names = "usb3-otg";
			dr_mode = "peripheral";
			maximum-speed = "high-speed";
			phys = <0x5a>;
			phy-names = "usb2-phy";
			phy_type = "utmi_wide";
			snps,dis_enblslpm_quirk;
			snps,dis-u2-freeclk-exists-quirk;
			snps,dis_u2_susphy_quirk;
			snps,dis-del-phy-power-chg-quirk;
			snps,dis-tx-ipgap-linecheck-quirk;
			snps,usb2-gadget-lpm-disable;
			snps,usb2-lpm-disable;
			status = "okay";
			extcon = <0x5b>;
		};
	};

	pinctrl {
		compatible = "rockchip,rv1106-pinctrl";
		rockchip,grf = <0x5c>;
		rockchip,pmu = <0x5d>;
		#address-cells = <0x01>;
		#size-cells = <0x01>;
		ranges;
		phandle = <0x5e>;

		gpio@ff380000 {
			compatible = "rockchip,gpio-bank";
			reg = <0xff380000 0x100>;
			interrupts = <0x00 0x05 0x04>;
			clocks = <0x02 0x70 0x02 0x71>;
			gpio-controller;
			#gpio-cells = <0x02>;
			gpio-ranges = <0x5e 0x00 0x00 0x20>;
			interrupt-controller;
			#interrupt-cells = <0x02>;
			phandle = <0x32>;
		};

		gpio@ff530000 {
			compatible = "rockchip,gpio-bank";
			reg = <0xff530000 0x100>;
			interrupts = <0x00 0x07 0x04>;
			clocks = <0x02 0xd4 0x02 0xd5>;
			gpio-controller;
			#gpio-cells = <0x02>;
			gpio-ranges = <0x5e 0x00 0x20 0x20>;
			interrupt-controller;
			#interrupt-cells = <0x02>;
			phandle = <0x2b>;
		};

		gpio@ff540000 {
			compatible = "rockchip,gpio-bank";
			reg = <0xff540000 0x100>;
			interrupts = <0x00 0x09 0x04>;
			clocks = <0x02 0xf9 0x02 0xfa>;
			gpio-controller;
			#gpio-cells = <0x02>;
			gpio-ranges = <0x5e 0x00 0x40 0x20>;
			interrupt-controller;
			#interrupt-cells = <0x02>;
			phandle = <0x6d>;
		};

		gpio@ff550000 {
			compatible = "rockchip,gpio-bank";
			reg = <0xff550000 0x100>;
			interrupts = <0x00 0x0b 0x04>;
			clocks = <0x02 0xe1 0x02 0xe2>;
			gpio-controller;
			#gpio-cells = <0x02>;
			gpio-ranges = <0x5e 0x00 0x60 0x20>;
			interrupt-controller;
			#interrupt-cells = <0x02>;
			phandle = <0x2d>;
		};

		gpio@ff560000 {
			compatible = "rockchip,gpio-bank";
			reg = <0xff560000 0x100>;
			interrupts = <0x00 0x0d 0x04>;
			clocks = <0x02 0x27 0x02 0x28>;
			gpio-controller;
			#gpio-cells = <0x02>;
			gpio-ranges = <0x5e 0x00 0x80 0x20>;
			interrupt-controller;
			#interrupt-cells = <0x02>;
		};

		pcfg-pull-up {
			bias-pull-up;
			phandle = <0x61>;
		};

		pcfg-pull-down {
			bias-pull-down;
			phandle = <0x67>;
		};

		pcfg-pull-none {
			bias-disable;
			phandle = <0x5f>;
		};

		pcfg-pull-none-drv-level-1 {
			bias-disable;
			drive-strength = <0x01>;
			phandle = <0x66>;
		};

		pcfg-pull-none-drv-level-2 {
			bias-disable;
			drive-strength = <0x02>;
			phandle = <0x65>;
		};

		pcfg-pull-none-drv-level-3 {
			bias-disable;
			drive-strength = <0x03>;
			phandle = <0x64>;
		};

		pcfg-pull-none-drv-level-4 {
			bias-disable;
			drive-strength = <0x04>;
			phandle = <0x63>;
		};

		pcfg-pull-up-drv-level-2 {
			bias-pull-up;
			drive-strength = <0x02>;
			phandle = <0x60>;
		};

		pcfg-pull-none-smt {
			bias-disable;
			input-schmitt-enable;
			phandle = <0x62>;
		};

		dsmaudio {

			dsmaudio-pins {
				rockchip,pins = <0x01 0x1b 0x07 0x5f 0x01 0x1a 0x07 0x5f>;
				phandle = <0x1e>;
			};
		};

		i2c0 {

			i2c0m0-xfer {
				rockchip,pins = <0x01 0x03 0x02 0x62 0x01 0x04 0x02 0x62>;
				phandle = <0x1c>;
			};
		};

		i2c1 {

			i2c1m1-xfer {
				rockchip,pins = <0x02 0x08 0x02 0x62 0x02 0x09 0x02 0x62>;
				phandle = <0x1d>;
			};
		};

		i2c2 {

			i2c2m0-xfer {
				rockchip,pins = <0x01 0x00 0x02 0x62 0x01 0x01 0x02 0x62>;
				phandle = <0x29>;
			};
		};

		i2c3 {

			i2c3m1-xfer {
				rockchip,pins = <0x01 0x1b 0x03 0x62 0x01 0x1a 0x03 0x62>;
				phandle = <0x2a>;
			};
		};

		i2c4 {

			i2c4m2-xfer {
				rockchip,pins = <0x03 0x17 0x03 0x62 0x03 0x18 0x03 0x62>;
				phandle = <0x2c>;
			};
		};

		mipi {

			mipi-pins {
				rockchip,pins = <0x03 0x10 0x02 0x5f 0x03 0x11 0x02 0x5f 0x03 0x0a 0x02 0x5f 0x03 0x0b 0x02 0x5f 0x03 0x12 0x02 0x5f 0x03 0x13 0x02 0x5f 0x03 0x0e 0x02 0x5f 0x03 0x0f 0x02 0x5f 0x03 0x0c 0x02 0x5f 0x03 0x0d 0x02 0x5f 0x03 0x08 0x02 0x5f 0x03 0x09 0x02 0x5f>;
				phandle = <0x13>;
			};

			mipi-refclk-out0 {
				rockchip,pins = <0x03 0x14 0x02 0x5f>;
				phandle = <0x2e>;
			};
		};

		pwm0 {

			pwm0m1-pins {
				rockchip,pins = <0x01 0x1a 0x06 0x5f>;
				phandle = <0x1f>;
			};
		};

		pwm1 {

			pwm1m0-pins {
				rockchip,pins = <0x00 0x04 0x02 0x5f>;
				phandle = <0x20>;
			};
		};

		pwm2 {

			pwm2m2-pins {
				rockchip,pins = <0x01 0x10 0x03 0x5f>;
				phandle = <0x21>;
			};
		};

		pwm3 {

			pwm3m2-pins {
				rockchip,pins = <0x01 0x18 0x03 0x5f>;
				phandle = <0x22>;
			};
		};

		pwm4 {

			pwm4m2-pins {
				rockchip,pins = <0x01 0x11 0x03 0x5f>;
				phandle = <0x23>;
			};
		};

		pwm5 {

			pwm5m2-pins {
				rockchip,pins = <0x01 0x12 0x03 0x5f>;
				phandle = <0x24>;
			};
		};

		pwm6 {

			pwm6m1-pins {
				rockchip,pins = <0x02 0x09 0x04 0x5f>;
				phandle = <0x25>;
			};

			pwm6m2-pins {
				rockchip,pins = <0x01 0x13 0x03 0x5f>;
				phandle = <0x26>;
			};
		};

		pwm7 {

			pwm7m0-pins {
				rockchip,pins = <0x01 0x00 0x03 0x5f>;
				phandle = <0x27>;
			};
		};

		pwm8 {

			pwm8m1-pins {
				rockchip,pins = <0x01 0x14 0x03 0x5f>;
				phandle = <0x33>;
			};
		};

		pwm9 {

			pwm9m1-pins {
				rockchip,pins = <0x01 0x15 0x03 0x5f>;
				phandle = <0x34>;
			};
		};

		pwm10 {

			pwm10m2-pins {
				rockchip,pins = <0x01 0x19 0x03 0x5f>;
				phandle = <0x35>;
			};
		};

		pwm11 {

			pwm11m1-pins {
				rockchip,pins = <0x01 0x17 0x03 0x5f>;
				phandle = <0x36>;
			};
		};

		sdmmc0 {

			sdmmc0-bus4 {
				rockchip,pins = <0x03 0x03 0x01 0x60 0x03 0x02 0x01 0x60 0x03 0x07 0x01 0x60 0x03 0x06 0x01 0x60>;
				phandle = <0x59>;
			};

			sdmmc0-clk {
				rockchip,pins = <0x03 0x04 0x01 0x60>;
				phandle = <0x56>;
			};

			sdmmc0-cmd {
				rockchip,pins = <0x03 0x05 0x01 0x60>;
				phandle = <0x57>;
			};

			sdmmc0-det {
				rockchip,pins = <0x03 0x01 0x01 0x61>;
				phandle = <0x58>;
			};
		};

		sdmmc1 {

			sdmmc1m0-bus4 {
				rockchip,pins = <0x02 0x01 0x01 0x60 0x02 0x00 0x01 0x60 0x02 0x05 0x01 0x60 0x02 0x04 0x01 0x60>;
				phandle = <0x4b>;
			};

			sdmmc1m0-clk {
				rockchip,pins = <0x02 0x02 0x01 0x60>;
				phandle = <0x49>;
			};

			sdmmc1m0-cmd {
				rockchip,pins = <0x02 0x03 0x01 0x60>;
				phandle = <0x4a>;
			};
		};

		spi0 {

			spi0m0-cs0 {
				rockchip,pins = <0x01 0x10 0x04 0x5f>;
				phandle = <0x43>;
			};

			spi0m0-clk {
				rockchip,pins = <0x01 0x11 0x04 0x5f>;
				phandle = <0x40>;
			};

			spi0m0-mosi {
				rockchip,pins = <0x01 0x12 0x06 0x5f>;
				phandle = <0x42>;
			};

			spi0m0-miso {
				rockchip,pins = <0x01 0x13 0x06 0x5f>;
				phandle = <0x41>;
			};
		};

		spi1 {

			spi1m0-pins {
				rockchip,pins = <0x04 0x07 0x02 0x5f 0x04 0x00 0x02 0x5f 0x04 0x01 0x02 0x5f>;
				phandle = <0x46>;
			};

			spi1m0-cs0 {
				rockchip,pins = <0x04 0x05 0x02 0x5f>;
				phandle = <0x44>;
			};

			spi1m0-cs1 {
				rockchip,pins = <0x01 0x09 0x03 0x5f>;
				phandle = <0x45>;
			};
		};

		uart0 {

			uart0m1-xfer {
				rockchip,pins = <0x02 0x08 0x01 0x61 0x02 0x09 0x01 0x61>;
				phandle = <0x38>;
			};

			uart0m1-ctsn {
				rockchip,pins = <0x02 0x07 0x01 0x5f>;
				phandle = <0x39>;
			};

			uart0m1-rtsn {
				rockchip,pins = <0x02 0x06 0x01 0x5f>;
				phandle = <0x3a>;
			};

			uart0-rts-gpio {
				rockchip,pins = <0x02 0x06 0x00 0x67>;
				phandle = <0x6e>;
			};
		};

		uart1 {

			uart1m1-xfer {
				rockchip,pins = <0x02 0x05 0x04 0x61 0x02 0x04 0x04 0x61>;
				phandle = <0x3b>;
			};
		};

		uart2 {

			uart2m1-xfer {
				rockchip,pins = <0x01 0x0b 0x02 0x61 0x01 0x0a 0x02 0x61>;
				phandle = <0x3c>;
			};
		};

		uart3 {

			uart3m1-xfer {
				rockchip,pins = <0x01 0x19 0x05 0x61 0x01 0x18 0x05 0x61>;
				phandle = <0x3d>;
			};
		};

		uart4 {

			uart4m1-xfer {
				rockchip,pins = <0x01 0x14 0x04 0x61 0x01 0x15 0x04 0x61>;
				phandle = <0x3e>;
			};
		};

		uart5 {

			uart5m0-xfer {
				rockchip,pins = <0x03 0x07 0x02 0x61 0x03 0x06 0x02 0x61>;
				phandle = <0x3f>;
			};
		};

		gpio0-pa4 {

			gpio0-pa4 {
				rockchip,pins = <0x00 0x04 0x00 0x5f>;
				phandle = <0x6c>;
			};
		};

		gpio1-pa0 {

			gpio1-pa0 {
				rockchip,pins = <0x01 0x00 0x00 0x5f>;
			};
		};

		gpio1-pa1 {

			gpio1-pa1 {
				rockchip,pins = <0x01 0x01 0x00 0x5f>;
			};
		};

		gpio1-pa2 {

			gpio1-pa2 {
				rockchip,pins = <0x01 0x02 0x00 0x5f>;
			};
		};

		gpio1-pa3 {

			gpio1-pa3 {
				rockchip,pins = <0x01 0x03 0x00 0x5f>;
			};
		};
	};

	rockchip-amp {
		compatible = "rockchip,amp";
		clocks = <0x02 0x3b 0x02 0x53 0x02 0x59 0x02 0x5f 0x02 0x42 0x02 0x123>;
		status = "okay";
	};

	adc-keys {
		compatible = "adc-keys";
		io-channels = <0x68 0x00>;
		io-channel-names = "buttons";
		poll-interval = <0x64>;
		keyup-threshold-microvolt = <0x1b7740>;

		key_volumeup-key {
			label = "key_volumeup";
			linux,code = <0x73>;
			press-threshold-microvolt = <0x00>;
		};

		key_volumedown-key {
			label = "key_volumedown";
			linux,code = <0x72>;
			press-threshold-microvolt = <0x61d8d>;
		};
	};

	restart-poweroff {
		compatible = "restart-poweroff";
	};

	chosen {
		bootargs = "earlycon=uart8250,mmio32,0xff4c0000 console=ttyFIQ0 root=/dev/mmcblk1p7 rootwait snd_soc_core.prealloc_buffer_size_kbytes=16 coherent_pool=0";
	};

	acodec-sound {
		compatible = "simple-audio-card";
		simple-audio-card,name = "rv-acodec";
		simple-audio-card,format = "i2s";
		simple-audio-card,mclk-fs = <0x100>;

		simple-audio-card,cpu {
			sound-dai = <0x69>;
		};

		simple-audio-card,codec {
			sound-dai = <0x6a>;
		};
	};

	vcc-1v8 {
		compatible = "regulator-fixed";
		regulator-name = "vcc_1v8";
		regulator-always-on;
		regulator-boot-on;
		regulator-min-microvolt = <0x1b7740>;
		regulator-max-microvolt = <0x1b7740>;
		phandle = <0x28>;
	};

	vcc-3v3 {
		compatible = "regulator-fixed";
		regulator-name = "vcc_3v3";
		regulator-always-on;
		regulator-boot-on;
		regulator-min-microvolt = <0x325aa0>;
		regulator-max-microvolt = <0x325aa0>;
	};

	vdd-arm {
		compatible = "regulator-fixed";
		regulator-name = "vdd_arm";
		regulator-min-microvolt = <0xdbba0>;
		regulator-max-microvolt = <0xdbba0>;
		regulator-always-on;
		regulator-boot-on;
		phandle = <0x04>;
	};

	leds {
		compatible = "gpio-leds";

		work {
			gpios = <0x32 0x03 0x00>;
			linux,default-trigger = "activity";
			default-state = "on";
		};
	};

	backlight {
		status = "okay";
		compatible = "pwm-backlight";
		pwms = <0x6b 0x00 0x493e0 0x00>;
		brightness-levels = <0x00 0x03 0x05 0x08 0x0a 0x0d 0x10 0x12 0x15 0x18 0x1a 0x1d 0x20 0x22 0x25 0x28 0x2a 0x2d 0x30 0x32 0x34 0x36 0x38 0x3a 0x3d 0x40 0x42 0x45 0x48 0x4a 0x4d 0x50 0x52 0x55 0x58 0x5a 0x5d 0x60 0x62 0x65 0x68 0x6a 0x6d 0x70 0x72 0x75 0x78 0x7a 0x7d 0x80 0x82 0x85 0x88 0x8a 0x8d 0x90 0x92 0x95 0x98 0x9a 0x9d 0xa0 0xa2 0xa5 0xa8 0xaa 0xad 0xb0 0xb2 0xb4 0xb6 0xb8 0xba 0xbc 0xbe 0xc0 0xc2 0xc5 0xc8 0xca 0xcd 0xd0 0xd2 0xd5 0xd8 0xda 0xdd 0xe0 0xe2 0xe5 0xe8 0xea 0xed 0xf0 0xf2 0xf5 0xf8 0xfa 0xfd 0xff>;
		default-brightness-level = <0x32>;
	};

	gpio0pa4 {
		compatible = "regulator-fixed";
		pinctrl-names = "default";
		pinctrl-0 = <0x6c>;
		regulator-name = "gpio0_pa4";
		regulator-always-on;
	};

	wireless-bluetooth {
		compatible = "bluetooth-platdata";
		uart_rts_gpios = <0x6d 0x06 0x01>;
		pinctrl-names = "default\0rts_gpio";
		pinctrl-0 = <0x3a>;
		pinctrl-1 = <0x6e>;
		BT,reset_gpio = <0x2b 0x02 0x00>;
		BT,wake_gpio = <0x2b 0x08 0x00>;
		BT,wake_host_irq = <0x2b 0x09 0x00>;
		status = "okay";
	};
};
